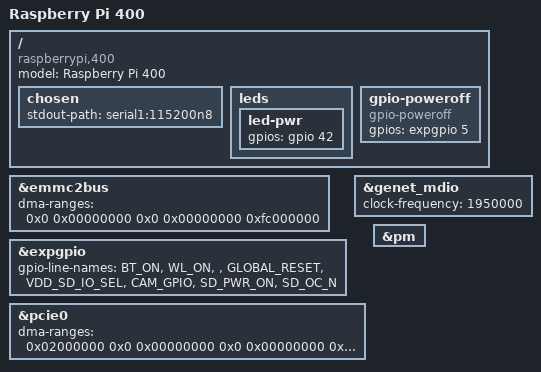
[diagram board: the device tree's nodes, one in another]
// SPDX-License-Identifier: GPL-2.0
/dts-v1/;
#include "bcm2711-rpi-4-b.dts"

/ {
	compatible = "raspberrypi,400", "brcm,bcm2711";
	model = "Raspberry Pi 400";

	chosen {
		/* 8250 auxiliary UART instead of pl011 */
		stdout-path = "serial1:115200n8";
	};

	leds {
		/delete-node/ led-act;

		led-pwr {
			gpios = <&gpio 42 GPIO_ACTIVE_HIGH>;
		};
	};

	gpio-poweroff {
		compatible = "gpio-poweroff";
		gpios = <&expgpio 5 GPIO_ACTIVE_HIGH>;
	};
};

&emmc2bus {
	dma-ranges = <0x0 0x00000000  0x0 0x00000000  0xfc000000>;
};

&expgpio {
	gpio-line-names = "BT_ON",
			  "WL_ON",
			  "",
			  "GLOBAL_RESET",
			  "VDD_SD_IO_SEL",
			  "CAM_GPIO",
			  "SD_PWR_ON",
			  "SD_OC_N";
};

&genet_mdio {
	clock-frequency = <1950000>;
};

&pcie0 {
	dma-ranges = <0x02000000 0x0 0x00000000 0x0 0x00000000 0x1 0x00000000>;
};

&pm {
	/delete-property/ system-power-controller;
};
